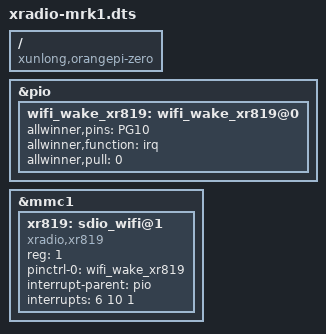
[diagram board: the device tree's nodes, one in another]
/dts-v1/;
/plugin/;

/ {
	compatible = "xunlong,orangepi-zero", "allwinner,sun8i-h2-plus";

	fragment@0 {
		target = <&pio>;
		__overlay__ {
			wifi_wake_xr819: wifi_wake_xr819@0 {
				allwinner,pins = "PG10";
				allwinner,function = "irq";
				allwinner,pull= <0>;
			};
		};
	};

	fragment@1 {
		target = <&mmc1>;
		__overlay__ {
			/delete-node/ xr819;
			xr819: sdio_wifi@1 {
				reg= <1>;
				compatible = "xradio,xr819";
				pinctrl-names = "default";
				pinctrl-0 = <&wifi_wake_xr819>;
				/* pinctrl-names = "default"; */
				/* pinctrl-0 = <&wifi_wake>; */
				interrupt-parent = <&pio>;
				interrupts = <6 10 1>;
				interrupt-names = "host-wake";
			};
		};
	};
};






